# PCIE1_CORE_USER_CFG_USER_CFG register map
Vendor: Texas Instruments
Peripheral module from a debugger description file (folder J721S2).
Registers are 32-bit, read-only, reset 0x0 unless marked. A register's access mark holds for its fields unless they carry their own. Offsets are as the file gives them; lines under a group give offsets from that group; [hi:lo] are bit positions; {n}, {i} and the like mark numbered series; 'fields as' and 'values as' point back to an identical list; <NAME> marks a mode.

## PCIE1_CORE_USER_CFG_USER_CFG
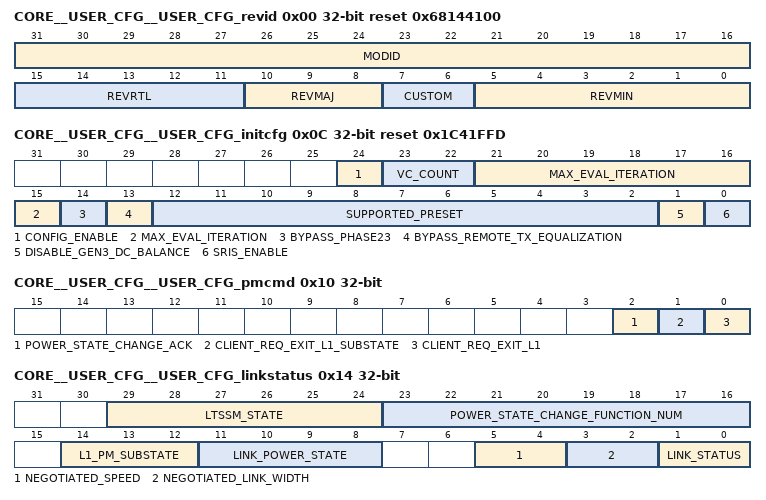
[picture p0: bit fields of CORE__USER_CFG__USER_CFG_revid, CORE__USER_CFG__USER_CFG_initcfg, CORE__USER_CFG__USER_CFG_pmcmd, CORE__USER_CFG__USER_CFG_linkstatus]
0x00 CORE__USER_CFG__USER_CFG_revid reset 0x68144100 — Module ID register
  [31:16] MODID — Module ID field
  [15:11] REVRTL — RTL revision. Will vary depending on release
  [10:8] REVMAJ — Major revision
  [7:6] CUSTOM
  [5:0] REVMIN — Minor revision
0x04 CORE__USER_CFG__USER_CFG_cmd_status rw — Command Status register
  [0] LINK_TRAINING_ENABLE — This bit must be set to 1 to enable the LTSSM to bring up the link. Setting it to 0 forces the LTSSM to stay in the Detect.Quiet state.
0x08 CORE__USER_CFG__USER_CFG_rstcmd rw — Reset Command and Status register
  [0] INIT_HOT_RESET — When this bit is set to 1'b1 in the RP mode, the core initiates a Hot Reset sequence on the PCIe link. The controller will keep the PCIe link in hot reset when this bit is asserted. When de-asserted, controller will bring the PCIe link out of hot reset and initiate link training. Valid in RP mode only
0x0C CORE__USER_CFG__USER_CFG_initcfg rw reset 0x1C41FFD — Initialization configuration register
  [24] CONFIG_ENABLE — When this bit is set to 0 in the EP mode, the Controller will generate a CRS Completion in response to Configuration Requests. When this bit is set to 1 in the EP mode, the Controller will generate SC/UR Completion in response to Configuration Requests based on the target function. In systems where the Controller configuration registers are loaded from RAM on power-up, this prevents the Controller from responding to Configuration Requests before all the registers are loaded. This bit is unused in RP Mode. The default value of this bit will be 1 in EP mode and 0 in RP mode
  [23:22] VC_COUNT — Number of VCs configured. 00 = 1 VC 01 = 2 VCs, 10 = 3 VCs, 11 = 4 VCs, .. and so on
  [21:15] MAX_EVAL_ITERATION — Denotes the maximum number of iterations to be performed during the DirectionChange Feedback Link Equalization in case the direction change feedback does not converge to 00. Supported values are 8-63. Recommended Value is from 8-16 to avoid the 24ms timeout as defined in PCIe spec.
  [14] BYPASS_PHASE23 — This MMR should be programmed during system boot or initialization. This is used only in Root Port Mode of the PCIe Core. If BYPASS_PHASE23==1: * Phase 2 AND Phase 3 of Link Equalization are bypassed during link equalization If BYPASS_PHASE23==0: * Phase 2 AND Phase 3 of Link Equalization are performed during link equalization
  [13] BYPASS_REMOTE_TX_EQUALIZATION — This MMR should be programmed during system boot or initialization. IF BYPASS_REMOTE_TX_EQUALIZATION==1: * In End-Point mode, Phase 2 of link equalization is bypassed * In Root-Port mode, Phase 3 of link equalization is bypassed IF BYPASS_REMOTE_TX_EQUALIZATION==0: * Remote TX Equalization is performed during link equalization
  [12:2] SUPPORTED_PRESET — This MMR should be programmed during system boot or initialization. SUPPORTED_PRESET[i]=1. Indicates Preset #i supported by PHY. SUPPORTED_PRESET[i]=0. Indicates Preset #i is not supported by PHY. * For Full Swing, all presets [P0 - P10] must be supported. * For Reduced Swing, [P4, P1, P9, P5, P6, P3] must be supported, others are optional as per PCIe spec.
  [1] DISABLE_GEN3_DC_BALANCE — This bit it is used to disable the transmission of special DC Balance symbols in TS1 training sequences for improving the DC balance of the bit stream at 8.0 GT/s or higher speed. This feature was introduced in the 0.71 version of the Gen3 spec. Setting this input to 1 disables the transmission of the special DC Balance symbols by the Controller. Note that the Controller can decode received training sequences with the special DC balance symbols in them correctly regardless of the setting of this input.
  [0] SRIS_ENABLE — Should be set as per the System Reference Clocking Implementation. 0 = Separate Tx and Rx Reference Clocks with No Spread Spectum Clocking - SRNS Mode 1 = Separate Tx and Rx Reference Clocks with Spread Spectum Clocking - SRIS Mode. This is the default setting. Note that the common Refclk architecture utilizes the same Refclk for Tx and Rx and so does not introduce any difference between the Tx and Rx Refclk rates. SRIS_ENABLE should be tied to 0 in this case also.
0x10 CORE__USER_CFG__USER_CFG_pmcmd rw — Power Management command register
  [2] POWER_STATE_CHANGE_ACK — Software must assert this bit for a minimum of one cycle in response to the assertion of POWER_STATE_CHANGE_INTERRUPT, when it is ready to transition to the low-power state requested by the configuration write request. Software may maintain this input high if it does not need to delay the return of the completions for the configuration write transactions causing power-state changes.
  [1] CLIENT_REQ_EXIT_L1_SUBSTATE — Client logic can trigger an explicit L1-substate exit by setting this bit. This bit triggers an exit from L1-substates to L0 if controller is already in L1- substates. Controller waits in L1 state for this signal to become de-asserted before entering L1-substate. Controller will respond to normal L1-exit triggers while it waits for de-assertion of this bit.
  [0] CLIENT_REQ_EXIT_L1 — Client logic can trigger an explicit L1 exit by setting this bit. This bit triggers an exit to L0 from L1 or from L1-substates. This bit can also be used to block L1 entry in End point controllers.
0x14 CORE__USER_CFG__USER_CFG_linkstatus — Link Status register
  [29:24] LTSSM_STATE — Current state of the Link Training and Status State Machine within the core. The encodings of this output are described in Appendix C of the Cadence User guide.
  [23:16] POWER_STATE_CHANGE_FUNCTION_NUM — Function number of the function for which a power state change occurred. Software can read this value when the power_state_change interrupt is asserted to determine the physical function for which the power state change occured.
  [14:12] L1_PM_SUBSTATE — This register provides the current state of the L1 PM substates state machine. Its encodings are: 000 = L1-substate machine not active 001 = L1.0 substate. L1_PM_SUBSTATE shows L1.0 after the delay programmed in L1 substate entry delay in reg:low_power_debug_control0 010 = L1.1 substate 011 = Reserved 100 = L1.2.Entry substate 101 = L1.2.Idle substate 110 = L1.2.Exit substate 111 = Reserved
  [11:8] LINK_POWER_STATE — Current power state of the PCIe link. 0001 = L0 0010 = L0s 0100 = L1 1000 = L2
  [5:4] NEGOTIATED_SPEED — Current operating speed of the link is as follows: 11: 16 GT/s 10: 8GT/s 01: 5GT/s 00: 2.5GT/s
  [3:2] NEGOTIATED_LINK_WIDTH — Current link width are as follows: 10: x4 01: x2 00: x1 Others: Reserved
  [1:0] LINK_STATUS — Status of the PCI Express link. 00 = No receivers detected. 01 = Link training in progress. 10 = Link up, DL initialization in progress. 11 = Link up, DL initialization completed.
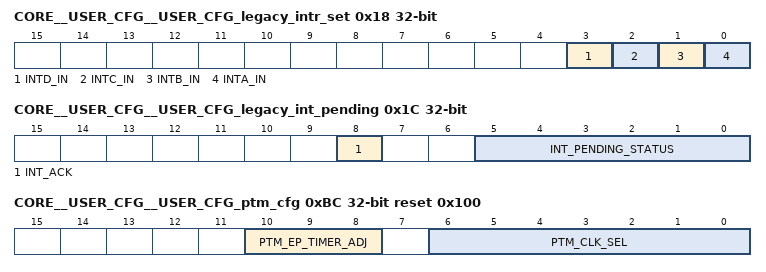
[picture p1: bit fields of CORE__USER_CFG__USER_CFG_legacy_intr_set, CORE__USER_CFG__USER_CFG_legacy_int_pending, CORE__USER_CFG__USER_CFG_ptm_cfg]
0x18 CORE__USER_CFG__USER_CFG_legacy_intr_set rw — Legacy interrupt set register
  [3] INTD_IN — When the core is configured as EP, this bit is used by the client application to signal an interrupt from any of its PCI Functions to the RP using the Legacy PCI Express Interrupt Delivery mechanism of PCI Express. This bit corresponds to INTD of the PCI bus. Asserting this bit causes the core to send out an Assert_INTx message, and de-asserting this bit causes the core to transmit a Deassert_INTx message.
  [2] INTC_IN — When the core is configured as EP, this bit is used by the client application to signal an interrupt from any of its PCI Functions to the RP using the Legacy PCI Express Interrupt Delivery mechanism of PCI Express. This bit corresponds to INTC of the PCI bus. Asserting this bit causes the core to send out an Assert_INTx message, and de-asserting this bit causes the core to transmit a Deassert_INTx message.
  [1] INTB_IN — When the core is configured as EP, this bit is used by the client application to signal an interrupt from any of its PCI Functions to the RP using the Legacy PCI Express Interrupt Delivery mechanism of PCI Express. This bit corresponds to INTB of the PCI bus. Asserting this bit causes the core to send out an Assert_INTx message, and de-asserting this bit causes the core to transmit a Deassert_INTx message.
  [0] INTA_IN — When the core is configured as EP, this bit is used by the client application to signal an interrupt from any of its PCI Functions to the RP using the Legacy PCI Express Interrupt Delivery mechanism of PCI Express. This bit corresponds to INTA of the PCI bus. Asserting this bit causes the core to send out an Assert_INTx message, and de-asserting this bit causes the core to transmit a Deassert_INTx message.
0x1C CORE__USER_CFG__USER_CFG_legacy_int_pending access not given — Legacy interrupt pending set register
  [8] INT_ACK — When using legacy interrupts, this bit indicates that the core has sent an INTx Assert or Deassert message in response to a change in the state of one of the INTx inputs. (access R/W1TC)
  [5:0] INT_PENDING_STATUS rw — When using legacy interrupts, this input is used to indicate the interrupt pending status of the Physical Functions. The bit i must be set when an interrupt is pending in Function i.
0x20 CORE__USER_CFG__USER_CFG_msi_stat — MSI status register
  [5:0] MSI_ENABLE — When the core is configured in the EndPoint mode to support MSI interrupts, this output is driven by the MSI Enable bit of the MSI Control Registers of the Physical Functions. Bit0 represents the MSI Enable for Physical Function0 and Bit1 represents the MSI Enable for Physical Function 1
0x24 CORE__USER_CFG__USER_CFG_msi_vector — MSI vector register
  [17:0] MSI_VECTOR_COUNT — When the core is configured in the EndPoint mode to support MSI interrupts, these outputs are driven by the Multiple Message Enable bits of the MSI Control Registers associated with Physical Functions. These bits encode the number of allocated MSI interrupt vectors for the corresponding Function. Bits[2:0] represents Physical Function0 and Bits[5:3] represents Physical Function 1
{0x28+4i} CORE__USER_CFG__USER_CFG_msi_mask_pf{i} (i=0..5) — PF{i} MSI mask register
  [31:0] MSI_MASK_PF{i} — These bits provide the setting of the MSI Mask registers of the Physical Function{i}.
0x40 CORE__USER_CFG__USER_CFG_msi_pending_status_pf0 rw — PF0 MSI pending status input register
  [31:0] MSI_PENDING_STATUS_PF0 — These inputs provide the status of the MSI pending interrupts for the Physical Function0 from the client to the core. If MSI Pending Status In Mode Select is set to 1 in the Debug Mux Control 2 register in local management,the setting of this register determines the value read from the MSI Pending Bits Register PF0.
{0x40+4i} CORE__USER_CFG__USER_CFG_msi_pending_status_pf{i} rw (i=1..5) — PF{i} MSI pending status input register
  [31:0] MSI_PENDING_STATUS_PF{i} — These inputs provide the status of the MSI pending interrupts for the Physical Function1 from the client to the core, if MSI Pending Status In Mode Select is set to 1 in the Debug Mux Control 2 register in local management,the setting of this register determines the value read from the MSI Pending Bits Register PF{i}.
0x58 CORE__USER_CFG__USER_CFG_msi_stat_vf — MSI_VF status register
  [15:0] VF_MSI_ENABLE — When the core is configured in the EndPoint mode to support MSI interrupts, this output is driven by the MSI Enable bit of the MSI Control Registers of the Virtual Functions. Bit0 represents the MSI Enable for Virtual Function0, Bit1 represents the MSI Enable for Virtual Function 1 and so on
0x5C CORE__USER_CFG__USER_CFG_msi_vector0_vf — MSI_VF vector count register0
  [23:0] VF_MSI_VECTOR_COUNT0 — When the core is configured in the Endpoint mode to support MSI interrupts, these outputs are driven by the Multiple Message Enable bits of the MSI Control Registers associated with Virtual Function0 thru Virtual Function7. These bits encode the number of allocated MSI interrupt vectors for the corresponding Function. Bits[2:0] represents Virtual Function0, Bits[5:3] represents Virtual Function 1 and so on
0x60 CORE__USER_CFG__USER_CFG_msi_vector1_vf — MSI_VF vector count register1
  [23:0] VF_MSI_VECTOR_COUNT1 — When the core is configured in the Endpoint mode to support MSI interrupts, these outputs are driven by the Multiple Message Enable bits of the MSI Control Registers associated with Virtual Function8 thru Virtual Function15. These bits encode the number of allocated MSI interrupt vectors for the corresponding Function. Bits[2:0] represents Virtual Function11, Bits[5:3] represents Virtual Function12 and so on
{0x64+4i} CORE__USER_CFG__USER_CFG_msi_mask_vf{i} (i=0..15) — VF{i}MSI mask register
  [31:0] MSI_MASK_VF{i} — These bits provide the setting of the MSI Mask registers of the Virtual Function{i}.
0xA4 CORE__USER_CFG__USER_CFG_msix_stat — MSIX status register
  [5:0] MSIX_ENABLE — These bits reflect the states of the MSI-X Enable bits in the PCI configuration space of Physical Functions.Bit0 represents the MSIX Enable for Physical Function0 and Bit1 represents the MSIX Enable for Physical Function 1
0xA8 CORE__USER_CFG__USER_CFG_msix_mask — MSIX mask register
  [5:0] MSIX_MASK — These bits reflect the states of the MSI-X Function Mask bits in the PCI configuration space of Physical Functions. Bit0 represents Physical Function0 and Bit1 represents Physical Function1
0xAC CORE__USER_CFG__USER_CFG_msix_stat_vf — Virtual Function MSIX status register
  [15:0] VF_MSIX_ENABLE — These bits reflect the states of the MSI-X Enable bits in the PCI configuration space of virtual Functions.Bit0 represents the MSIX Enable for Virtual Function0, Bit1 represents the MSIX Enable for Virtual Function 1 and so on
0xB0 CORE__USER_CFG__USER_CFG_msix_mask_vf — Virtual Function MSIX mask register
  [15:0] VF_MSIX_MASK — These bits reflect the states of the MSI-X Function Mask bits in the PCI configuration space of Virtual Functions. Bit0 represents Virtual Function0, Bit1 represents Virtual Function1 and so on
0xB4 CORE__USER_CFG__USER_CFG_flr_done wo — Physical Function-Level Reset Done register
  [5:0] FLR_DONE — These bits are connected to the FLR_DONE bits on the PCIe controller core. In EP mode, software needs to write a 1 to bit0 within 100ms after PF0 function-level reset interrupt is asserted. The FLR_DONE[0] input of the PCIe controller is pulsed for one cycle to acknowledge to the core that the application level function level reset processing is complete. This bit will self-clear once the FLR_DONE[0] is pulsed. The PCIe controller will maintain FLR_IN_PROGRESS[0] output high until it is acknowledged by asserting FLR_DONE. Bit 1 is used to acknowledge FLR_DONE for PF1. These bits are not used in RP mode
0xB8 CORE__USER_CFG__USER_CFG_vf_flr_done wo — Virtual Function-Level Reset Done register
  [15:0] VF_FLR_DONE — These bits are connected to the VF_FLR_DONE bits on the PCIe controller core. In EP mode, software needs to write a 1 to bit0 within 100ms after VF0 function-level reset interrupt is asserted. The VF_FLR_DONE[0] input of the PCIe controller is pulsed for one cycle to acknowledge to the core that the application level virtual function level reset processing is complete. This bit will self-clear once the VF_FLR_DONE[0] is pulsed The PCIe controller will maintain VF_FLR_IN_PROGRESS[0] output high until it is acknowledged by asserting VF_FLR_DONE[0]. Bit 1 is used to acknowledge VF_FLR_DONE for VF1, bit2 is used to acknowledge VF_FLR_DONE for VF2 and so on. These bits are not used in RP mode
0xBC CORE__USER_CFG__USER_CFG_ptm_cfg rw reset 0x100 — PTM Timestamp configuration register
  [10:8] PTM_EP_TIMER_ADJ — PTM EP Timer tick adjust value. 1 will increment ptm_ep_timer by 1 each clock cycle, 2 will increment the timer by 2 .. 7 will increment the timer by 7. The adjust value should be set prior to enabling PTM operation in the PCIe controller.
  [6:0] PTM_CLK_SEL — Select CPTS HW1 push input. 0 will select ptm_local_timer[0], 1 will select ptm_local_timer[1] ... 63 will select ptm_local_timer[63] and 64 will select ptm_local_timer_out_valid. The values 65 to 127 are unused. The PTM clock select bit should be set prior to enabling the PTM operation in the PCIe controller
0xC0 CORE__USER_CFG__USER_CFG_ptm_timer_low — PTM timer value lower 32-bits
  [31:0] PTM_TIMER_OUT_LOW — ptm_timer_out[31:0] value from PCIe core. Valid in EP mode only
0xC4 CORE__USER_CFG__USER_CFG_ptm_timer_high — PTM timer value upper 32-bits
  [31:0] PTM_TIMER_OUT_HIGH — ptm_timer_out[63:32] value from PCIe core. Valid in EP mode only
0xC8 CORE__USER_CFG__USER_CFG_eoi_vector rw — EOI vector for re-triggering interrupts
  [7:0] EOI_VECTOR — EOI vector for level interrupts. Writing the EOI value as specfied to this register will re-trigger a pending interrupt. 0 - Downstream interrupt, 1 - FLR interrupt, 2 - Legacy interrupt, 3 - Power state interrupt
